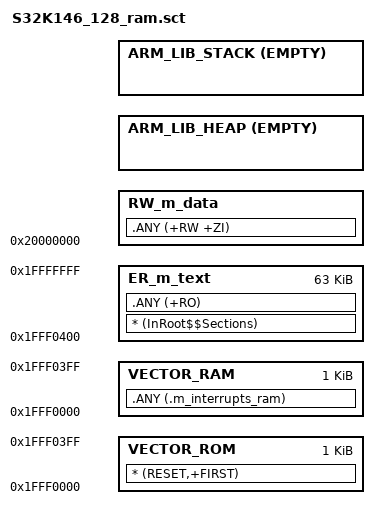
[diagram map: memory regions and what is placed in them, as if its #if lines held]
#! armcc -E
/*
** ###################################################################
**     Processor:           S32K144 with 64 KB SRAM
**     Compiler:            Keil ARM C/C++ Compiler
**
**     Abstract:
**         Linker file for the GNU C Compiler
**
**     Copyright (c) 2015-2016 Freescale Semiconductor, Inc.
**     Copyright 2017 NXP
**     All rights reserved.
**
**     THIS SOFTWARE IS PROVIDED BY NXP "AS IS" AND ANY EXPRESSED OR
**     IMPLIED WARRANTIES, INCLUDING, BUT NOT LIMITED TO, THE IMPLIED WARRANTIES
**     OF MERCHANTABILITY AND FITNESS FOR A PARTICULAR PURPOSE ARE DISCLAIMED.
**     IN NO EVENT SHALL NXP OR ITS CONTRIBUTORS BE LIABLE FOR ANY DIRECT,
**     INDIRECT, INCIDENTAL, SPECIAL, EXEMPLARY, OR CONSEQUENTIAL DAMAGES
**     (INCLUDING, BUT NOT LIMITED TO, PROCUREMENT OF SUBSTITUTE GOODS OR
**     SERVICES; LOSS OF USE, DATA, OR PROFITS; OR BUSINESS INTERRUPTION)
**     HOWEVER CAUSED AND ON ANY THEORY OF LIABILITY, WHETHER IN CONTRACT,
**     STRICT LIABILITY, OR TORT (INCLUDING NEGLIGENCE OR OTHERWISE) ARISING
**     IN ANY WAY OUT OF THE USE OF THIS SOFTWARE, EVEN IF ADVISED OF
**     THE POSSIBILITY OF SUCH DAMAGE.
**
**     http:                 www.nxp.com
**     mail:                 support@nxp.com
**
** ###################################################################
*/

#define m_interrupts_start             0x1FFF0000
#define m_interrupts_size              0x00000400

#define m_data_start                   0x20000000
#define m_data_size                    0x0000F000

#define m_text_start                   0x1FFF0400
#define m_text_size                    0x0000FC00

/* Sizes */
#if (defined(__stack_size__))
  #define Stack_Size                   __stack_size__
#else
  #define Stack_Size                   0x0400
#endif

#if (defined(__heap_size__))
  #define Heap_Size                    __heap_size__
#else
  #define Heap_Size                    0x0400
#endif

LR_m_text m_text_start m_text_size {   ; load region size_region
  ER_m_text m_text_start m_text_size { ; load address = execution address
    * (InRoot$$Sections)
    .ANY (+RO)
  }
  RW_m_data m_data_start m_data_size-Stack_Size-Heap_Size { ; RW data
    .ANY (+RW +ZI)
  }
  ARM_LIB_HEAP +0 EMPTY Heap_Size {    ; Heap region growing up
  }
  ARM_LIB_STACK m_data_start+m_data_size EMPTY -Stack_Size { ; Stack region growing down
  }
}

LR_m_interrupts m_interrupts_start m_interrupts_size {
  VECTOR_ROM m_interrupts_start m_interrupts_size { ; load address = execution address
    * (RESET,+FIRST)
  }
}

LR_m_interrupts_ram m_interrupts_start m_interrupts_size {
  VECTOR_RAM m_interrupts_start m_interrupts_size { ; load address = execution address
    .ANY (.m_interrupts_ram)
  }
}

